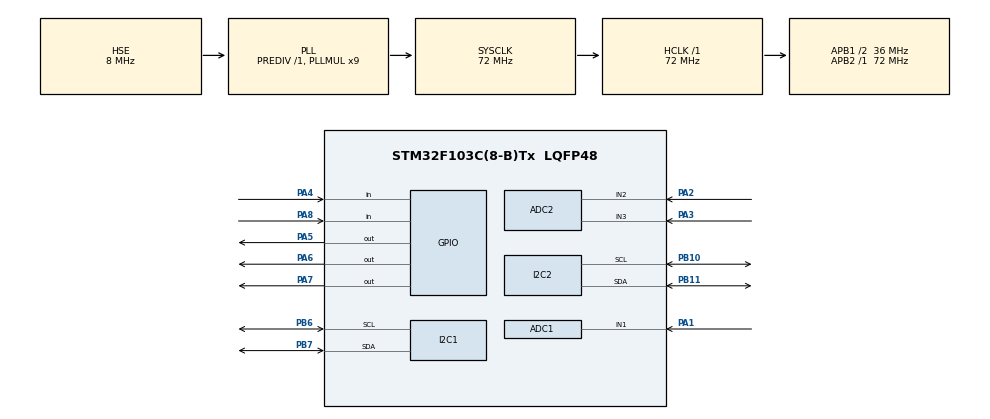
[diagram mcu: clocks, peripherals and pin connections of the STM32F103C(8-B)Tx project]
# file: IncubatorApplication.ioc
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ADC1.Channel-2\#ChannelRegularConversion=ADC_CHANNEL_1
ADC1.ContinuousConvMode=ENABLE
ADC1.NbrOfConversion=1
ADC1.NbrOfConversionFlag=1
ADC1.Rank-2\#ChannelRegularConversion=1
ADC1.SamplingTime-2\#ChannelRegularConversion=ADC_SAMPLETIME_13CYCLES_5
ADC1.master=1
ADC2.Channel-4\#ChannelRegularConversion=ADC_CHANNEL_2
ADC2.NbrOfConversion=1
ADC2.NbrOfConversionFlag=1
ADC2.Rank-4\#ChannelRegularConversion=1
ADC2.SamplingTime-4\#ChannelRegularConversion=ADC_SAMPLETIME_13CYCLES_5
Mcu.Family=STM32F1
Mcu.Name=STM32F103C(8-B)Tx
Mcu.Package=LQFP48
NVIC.PriorityGroup=NVIC_PRIORITYGROUP_4
PA1.Signal=ADCx_IN1
PA2.Signal=ADCx_IN2
PA3.Signal=ADCx_IN3
PA4.GPIO_PuPd=GPIO_PULLUP
PA4.Signal=GPIO_Input
PA5.GPIO_PuPd=GPIO_PULLDOWN
PA5.GPIO_Speed=GPIO_SPEED_FREQ_MEDIUM
PA5.Signal=GPIO_Output
PA6.GPIO_PuPd=GPIO_PULLDOWN
PA6.GPIO_Speed=GPIO_SPEED_FREQ_MEDIUM
PA6.Signal=GPIO_Output
PA7.Signal=GPIO_Output
PA8.Signal=GPIO_Input
PB10.Mode=I2C
PB10.Signal=I2C2_SCL
PB11.Mode=I2C
PB11.Signal=I2C2_SDA
PB6.Mode=I2C
PB6.Signal=I2C1_SCL
PB7.Mode=I2C
PB7.Signal=I2C1_SDA
PD0-OSC_IN.Mode=HSE-External-Oscillator
PD0-OSC_IN.Signal=RCC_OSC_IN
PD1-OSC_OUT.Mode=HSE-External-Oscillator
PD1-OSC_OUT.Signal=RCC_OSC_OUT
ProjectManager.HeapSize=0x200
ProjectManager.StackSize=0x400
ProjectManager.TargetToolchain=STM32CubeIDE
RCC.ADCPresc=RCC_ADCPCLK2_DIV6
RCC.AHBFreq_Value=72000000
RCC.APB1CLKDivider=RCC_HCLK_DIV2
RCC.APB1Freq_Value=36000000
RCC.APB1TimFreq_Value=72000000
RCC.APB2Freq_Value=72000000
RCC.APB2TimFreq_Value=72000000
RCC.HCLKFreq_Value=72000000
RCC.PLLMUL=RCC_PLL_MUL9
RCC.PLLSourceVirtual=RCC_PLLSOURCE_HSE
RCC.SYSCLKFreq_VALUE=72000000
RCC.SYSCLKSource=RCC_SYSCLKSOURCE_PLLCLK
RCC.USBFreq_Value=72000000
SH.ADCx_IN1.0=ADC1_IN1,IN1
SH.ADCx_IN2.0=ADC2_IN2,IN2
SH.ADCx_IN3.0=ADC2_IN3,IN3
TIM4.Prescaler=72 - 1
VP_SYS_VS_ND.Mode=No_Debug
VP_TIM4_VS_ClockSourceINT.Mode=Internal
board=custom

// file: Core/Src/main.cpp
/* USER CODE BEGIN Header */
/**
  ******************************************************************************
  * @file           : main.c
  * @brief          : Main program body
  ******************************************************************************
  * @attention
  *
  * Copyright (c) 2025 STMicroelectronics.
  * All rights reserved.
  *
  * This software is licensed under terms that can be found in the LICENSE file
  * in the root directory of this software component.
  * If no LICENSE file comes with this software, it is provided AS-IS.
  *
  ******************************************************************************
  */
/* USER CODE END Header */
#include "main.h"

/* USER CODE BEGIN Includes */

#include "Incubator/IncubatorApp.h"
/* USER CODE END Includes */

ADC_HandleTypeDef hadc1;
ADC_HandleTypeDef hadc2;

I2C_HandleTypeDef hi2c1;
I2C_HandleTypeDef hi2c2;

TIM_HandleTypeDef htim4;

void SystemClock_Config(void);
static void MX_GPIO_Init(void);
static void MX_I2C1_Init(void);
static void MX_TIM4_Init(void);
static void MX_ADC1_Init(void);
static void MX_I2C2_Init(void);
static void MX_ADC2_Init(void);

int main(void)
{

  /* MCU Configuration--------------------------------------------------------*/

  /* Reset of all peripherals, Initializes the Flash interface and the Systick. */
  HAL_Init();

  /* Configure the system clock */
  SystemClock_Config();

  /* Initialize all configured peripherals */
  MX_GPIO_Init();
  MX_I2C1_Init();
  MX_TIM4_Init();
  MX_ADC1_Init();
  MX_I2C2_Init();
  MX_ADC2_Init();

  /* Infinite loop */
  /* USER CODE BEGIN WHILE */

	static Incubator::IncubatorApp s_IncubatorApp;
  s_IncubatorApp.Initialize();
  while (1)
  {
    /* USER CODE END WHILE */

    /* USER CODE BEGIN 3 */
    s_IncubatorApp.Run();
  }
  /* USER CODE END 3 */
}

void SystemClock_Config(void)
{
  RCC_OscInitTypeDef RCC_OscInitStruct = {0};
  RCC_ClkInitTypeDef RCC_ClkInitStruct = {0};
  RCC_PeriphCLKInitTypeDef PeriphClkInit = {0};

  /** Initializes the RCC Oscillators according to the specified parameters
  * in the RCC_OscInitTypeDef structure.
  */
  RCC_OscInitStruct.OscillatorType = RCC_OSCILLATORTYPE_HSE;
  RCC_OscInitStruct.HSEState = RCC_HSE_ON;
  RCC_OscInitStruct.HSEPredivValue = RCC_HSE_PREDIV_DIV1;
  RCC_OscInitStruct.HSIState = RCC_HSI_ON;
  RCC_OscInitStruct.PLL.PLLState = RCC_PLL_ON;
  RCC_OscInitStruct.PLL.PLLSource = RCC_PLLSOURCE_HSE;
  RCC_OscInitStruct.PLL.PLLMUL = RCC_PLL_MUL9;
  if (HAL_RCC_OscConfig(&RCC_OscInitStruct) != HAL_OK)
  {
    Error_Handler();
  }

  /** Initializes the CPU, AHB and APB buses clocks
  */
  RCC_ClkInitStruct.ClockType = RCC_CLOCKTYPE_HCLK|RCC_CLOCKTYPE_SYSCLK
                              |RCC_CLOCKTYPE_PCLK1|RCC_CLOCKTYPE_PCLK2;
  RCC_ClkInitStruct.SYSCLKSource = RCC_SYSCLKSOURCE_PLLCLK;
  RCC_ClkInitStruct.AHBCLKDivider = RCC_SYSCLK_DIV1;
  RCC_ClkInitStruct.APB1CLKDivider = RCC_HCLK_DIV2;
  RCC_ClkInitStruct.APB2CLKDivider = RCC_HCLK_DIV1;

  if (HAL_RCC_ClockConfig(&RCC_ClkInitStruct, FLASH_LATENCY_2) != HAL_OK)
  {
    Error_Handler();
  }
  PeriphClkInit.PeriphClockSelection = RCC_PERIPHCLK_ADC;
  PeriphClkInit.AdcClockSelection = RCC_ADCPCLK2_DIV6;
  if (HAL_RCCEx_PeriphCLKConfig(&PeriphClkInit) != HAL_OK)
  {
    Error_Handler();
  }
}

static void MX_ADC1_Init(void)
{

  ADC_ChannelConfTypeDef sConfig = {0};

  /** Common config
  */
  hadc1.Instance = ADC1;
  hadc1.Init.ScanConvMode = ADC_SCAN_DISABLE;
  hadc1.Init.ContinuousConvMode = ENABLE;
  hadc1.Init.DiscontinuousConvMode = DISABLE;
  hadc1.Init.ExternalTrigConv = ADC_SOFTWARE_START;
  hadc1.Init.DataAlign = ADC_DATAALIGN_RIGHT;
  hadc1.Init.NbrOfConversion = 1;
  if (HAL_ADC_Init(&hadc1) != HAL_OK)
  {
    Error_Handler();
  }

  /** Configure Regular Channel
  */
  sConfig.Channel = ADC_CHANNEL_1;
  sConfig.Rank = ADC_REGULAR_RANK_1;
  sConfig.SamplingTime = ADC_SAMPLETIME_13CYCLES_5;
  if (HAL_ADC_ConfigChannel(&hadc1, &sConfig) != HAL_OK)
  {
    Error_Handler();
  }

}

static void MX_ADC2_Init(void)
{

  ADC_ChannelConfTypeDef sConfig = {0};

  /** Common config
  */
  hadc2.Instance = ADC2;
  hadc2.Init.ScanConvMode = ADC_SCAN_DISABLE;
  hadc2.Init.ContinuousConvMode = DISABLE;
  hadc2.Init.DiscontinuousConvMode = DISABLE;
  hadc2.Init.ExternalTrigConv = ADC_SOFTWARE_START;
  hadc2.Init.DataAlign = ADC_DATAALIGN_RIGHT;
  hadc2.Init.NbrOfConversion = 1;
  if (HAL_ADC_Init(&hadc2) != HAL_OK)
  {
    Error_Handler();
  }

  /** Configure Regular Channel
  */
  sConfig.Channel = ADC_CHANNEL_2;
  sConfig.Rank = ADC_REGULAR_RANK_1;
  sConfig.SamplingTime = ADC_SAMPLETIME_13CYCLES_5;
  if (HAL_ADC_ConfigChannel(&hadc2, &sConfig) != HAL_OK)
  {
    Error_Handler();
  }

}

static void MX_I2C1_Init(void)
{

  hi2c1.Instance = I2C1;
  hi2c1.Init.ClockSpeed = 100000;
  hi2c1.Init.DutyCycle = I2C_DUTYCYCLE_2;
  hi2c1.Init.OwnAddress1 = 0;
  hi2c1.Init.AddressingMode = I2C_ADDRESSINGMODE_7BIT;
  hi2c1.Init.DualAddressMode = I2C_DUALADDRESS_DISABLE;
  hi2c1.Init.OwnAddress2 = 0;
  hi2c1.Init.GeneralCallMode = I2C_GENERALCALL_DISABLE;
  hi2c1.Init.NoStretchMode = I2C_NOSTRETCH_DISABLE;
  if (HAL_I2C_Init(&hi2c1) != HAL_OK)
  {
    Error_Handler();
  }

}

static void MX_I2C2_Init(void)
{

  hi2c2.Instance = I2C2;
  hi2c2.Init.ClockSpeed = 100000;
  hi2c2.Init.DutyCycle = I2C_DUTYCYCLE_2;
  hi2c2.Init.OwnAddress1 = 0;
  hi2c2.Init.AddressingMode = I2C_ADDRESSINGMODE_7BIT;
  hi2c2.Init.DualAddressMode = I2C_DUALADDRESS_DISABLE;
  hi2c2.Init.OwnAddress2 = 0;
  hi2c2.Init.GeneralCallMode = I2C_GENERALCALL_DISABLE;
  hi2c2.Init.NoStretchMode = I2C_NOSTRETCH_DISABLE;
  if (HAL_I2C_Init(&hi2c2) != HAL_OK)
  {
    Error_Handler();
  }

}

static void MX_TIM4_Init(void)
{

  TIM_ClockConfigTypeDef sClockSourceConfig = {0};
  TIM_MasterConfigTypeDef sMasterConfig = {0};

  htim4.Instance = TIM4;
  htim4.Init.Prescaler = 72 - 1;
  htim4.Init.CounterMode = TIM_COUNTERMODE_UP;
  htim4.Init.Period = 65535;
  htim4.Init.ClockDivision = TIM_CLOCKDIVISION_DIV1;
  htim4.Init.AutoReloadPreload = TIM_AUTORELOAD_PRELOAD_DISABLE;
  if (HAL_TIM_Base_Init(&htim4) != HAL_OK)
  {
    Error_Handler();
  }
  sClockSourceConfig.ClockSource = TIM_CLOCKSOURCE_INTERNAL;
  if (HAL_TIM_ConfigClockSource(&htim4, &sClockSourceConfig) != HAL_OK)
  {
    Error_Handler();
  }
  sMasterConfig.MasterOutputTrigger = TIM_TRGO_RESET;
  sMasterConfig.MasterSlaveMode = TIM_MASTERSLAVEMODE_DISABLE;
  if (HAL_TIMEx_MasterConfigSynchronization(&htim4, &sMasterConfig) != HAL_OK)
  {
    Error_Handler();
  }

}

static void MX_GPIO_Init(void)
{
  GPIO_InitTypeDef GPIO_InitStruct = {0};

  /* GPIO Ports Clock Enable */
  __HAL_RCC_GPIOD_CLK_ENABLE();
  __HAL_RCC_GPIOA_CLK_ENABLE();
  __HAL_RCC_GPIOB_CLK_ENABLE();

  /*Configure GPIO pin Output Level */
  HAL_GPIO_WritePin(GPIOA, GPIO_PIN_5|GPIO_PIN_6|GPIO_PIN_7, GPIO_PIN_RESET);

  /*Configure GPIO pin : PA4 */
  GPIO_InitStruct.Pin = GPIO_PIN_4;
  GPIO_InitStruct.Mode = GPIO_MODE_INPUT;
  GPIO_InitStruct.Pull = GPIO_PULLUP;
  HAL_GPIO_Init(GPIOA, &GPIO_InitStruct);

  /*Configure GPIO pins : PA5 PA6 */
  GPIO_InitStruct.Pin = GPIO_PIN_5|GPIO_PIN_6;
  GPIO_InitStruct.Mode = GPIO_MODE_OUTPUT_PP;
  GPIO_InitStruct.Pull = GPIO_PULLDOWN;
  GPIO_InitStruct.Speed = GPIO_SPEED_FREQ_MEDIUM;
  HAL_GPIO_Init(GPIOA, &GPIO_InitStruct);

  /*Configure GPIO pin : PA7 */
  GPIO_InitStruct.Pin = GPIO_PIN_7;
  GPIO_InitStruct.Mode = GPIO_MODE_OUTPUT_PP;
  GPIO_InitStruct.Pull = GPIO_NOPULL;
  GPIO_InitStruct.Speed = GPIO_SPEED_FREQ_LOW;
  HAL_GPIO_Init(GPIOA, &GPIO_InitStruct);

  /*Configure GPIO pin : PA8 */
  GPIO_InitStruct.Pin = GPIO_PIN_8;
  GPIO_InitStruct.Mode = GPIO_MODE_INPUT;
  GPIO_InitStruct.Pull = GPIO_NOPULL;
  HAL_GPIO_Init(GPIOA, &GPIO_InitStruct);

}

void Error_Handler(void)
{
  __disable_irq();
  while (1)
  {
  }
}
